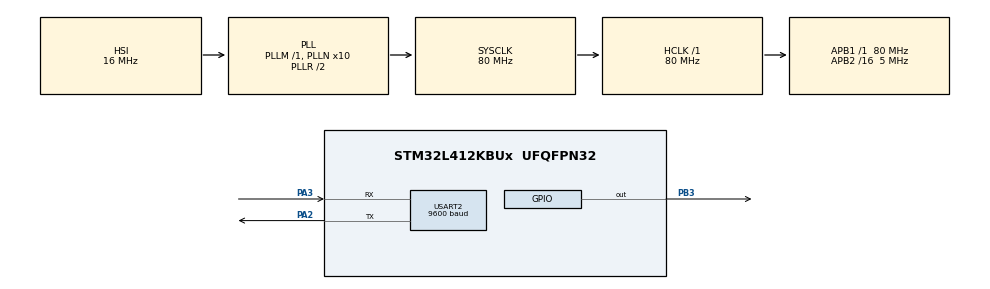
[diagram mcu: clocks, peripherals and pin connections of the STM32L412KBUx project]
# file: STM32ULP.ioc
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Mcu.Family=STM32L4
Mcu.Name=STM32L412KBUx
Mcu.Package=UFQFPN32
NVIC.PriorityGroup=NVIC_PRIORITYGROUP_4
NVIC.RTC_WKUP_IRQn=true\:0\:0\:false\:false\:true\:true\:true\:true
PA2.Mode=Asynchronous
PA2.Signal=USART2_TX
PA3.Mode=Asynchronous
PA3.Signal=USART2_RX
PB3\ (JTDO/TRACESWO).Signal=GPIO_Output
ProjectManager.HeapSize=0x200
ProjectManager.StackSize=0x400
ProjectManager.TargetToolchain=STM32CubeIDE
RCC.ADCFreq_Value=80000000
RCC.AHBFreq_Value=80000000
RCC.APB1Freq_Value=80000000
RCC.APB1TimFreq_Value=80000000
RCC.APB2CLKDivider=RCC_HCLK_DIV16
RCC.APB2Freq_Value=5000000
RCC.APB2TimFreq_Value=10000000
RCC.CortexFreq_Value=10000000
RCC.Cortex_Div=SYSTICK_CLKSOURCE_HCLK_DIV8
RCC.HCLKFreq_Value=80000000
RCC.HSE_VALUE=8000000
RCC.HSI48_VALUE=48000000
RCC.HSI_VALUE=16000000
RCC.LSE_VALUE=32768
RCC.MSIClockRange=RCC_MSIRANGE_11
RCC.MSI_VALUE=48000000
RCC.PLLN=10
RCC.PLLSourceVirtual=RCC_PLLSOURCE_HSI
RCC.SYSCLKFreq_VALUE=80000000
RCC.SYSCLKSource=RCC_SYSCLKSOURCE_PLLCLK
RCC.USART1CLockSelection=RCC_USART1CLKSOURCE_HSI
RCC.USART2CLockSelection=RCC_USART2CLKSOURCE_SYSCLK
RCC.USBFreq_Value=48000000
RCC.VCOOutputFreq_Value=160000000
RTC.WakeUpClock=RTC_WAKEUPCLOCK_RTCCLK_DIV16
RTC.WakeUpCounter=20490
USART2.BaudRate=9600
USART2.VirtualMode-Asynchronous=VM_ASYNC
VP_RTC_VS_RTC_Activate.Mode=RTC_Enabled
VP_RTC_VS_RTC_WakeUp_intern.Mode=WakeUp
VP_SYS_VS_DBSignals.Mode=DisableDeadBatterySignals
board=custom

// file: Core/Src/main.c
/* USER CODE BEGIN Header */
/**
  ******************************************************************************
  * @file           : main.c
  * @brief          : Main program body
  ******************************************************************************
  * @attention
  *
  * Copyright (c) 2024 STMicroelectronics.
  * All rights reserved.
  *
  * This software is licensed under terms that can be found in the LICENSE file
  * in the root directory of this software component.
  * If no LICENSE file comes with this software, it is provided AS-IS.
  *
  ******************************************************************************
  */
#include <stdio.h>
/* USER CODE END Header */
#include "main.h"

RTC_HandleTypeDef hrtc;

UART_HandleTypeDef huart2;

void SystemClock_Config(void);
static void MX_GPIO_Init(void);
static void MX_RTC_Init(void);
static void MX_USART2_UART_Init(void);

/* USER CODE BEGIN 0 */
void HAL_UARTEx_EnableLowPower(UART_HandleTypeDef *huart) {
    // This function ensures that UART remains active in low-power modes
    if (huart->Instance == USART2) {
        __HAL_RCC_USART2_CLK_ENABLE();  // Ensure USART2 clock is enabled
        huart->Init.Mode = UART_MODE_TX_RX;  // Ensure both TX and RX are enabled
        huart->Init.OverSampling = UART_OVERSAMPLING_16;  // OverSampling

        // Apply the configuration changes
        if (HAL_UART_Init(huart) != HAL_OK) {
            // Initialization error, handle it here
            Error_Handler();
        }
    }
}

/* USER CODE END 0 */

int main(void)
{

  /* USER CODE BEGIN 1 */
	char MSG[46] = {'\0'};

  /* USER CODE END 1 */

  /* MCU Configuration--------------------------------------------------------*/

  /* Reset of all peripherals, Initializes the Flash interface and the Systick. */
  HAL_Init();

  /* Configure the system clock */
  SystemClock_Config();

  /* Initialize all configured peripherals */
  MX_GPIO_Init();
  MX_RTC_Init();
  MX_USART2_UART_Init();

  /* Infinite loop */
  /* USER CODE BEGIN WHILE */
  while (1)
  {
	  // Reconfigure system clocks after waking up
	  SystemClock_Config();

	  // Reinitialize UART
	  HAL_UART_Init(&huart2);

	  //Print value stored in backup register to serial port
	  sprintf(MSG,"Value in backup register 7 is: %lu \r\n", HAL_RTCEx_BKUPRead(&hrtc, RTC_BKP_DR7));
	  HAL_UART_Transmit(&huart2, MSG, sizeof(MSG),HAL_MAX_DELAY);

	  //Enter STOP mode
	  HAL_PWR_EnterSTOPMode(PWR_LOWPOWERREGULATOR_ON, PWR_STOPENTRY_WFI);
    /* USER CODE END WHILE */

    /* USER CODE BEGIN 3 */
	 // Once the system wakes up, reinitialize clocks and UART

  }
  /* USER CODE END 3 */
}

void SystemClock_Config(void)
{
  RCC_OscInitTypeDef RCC_OscInitStruct = {0};
  RCC_ClkInitTypeDef RCC_ClkInitStruct = {0};

  /** Configure the main internal regulator output voltage
  */
  if (HAL_PWREx_ControlVoltageScaling(PWR_REGULATOR_VOLTAGE_SCALE1) != HAL_OK)
  {
    Error_Handler();
  }

  /** Initializes the RCC Oscillators according to the specified parameters
  * in the RCC_OscInitTypeDef structure.
  */
  RCC_OscInitStruct.OscillatorType = RCC_OSCILLATORTYPE_HSI|RCC_OSCILLATORTYPE_LSI;
  RCC_OscInitStruct.HSIState = RCC_HSI_ON;
  RCC_OscInitStruct.HSICalibrationValue = RCC_HSICALIBRATION_DEFAULT;
  RCC_OscInitStruct.LSIState = RCC_LSI_ON;
  RCC_OscInitStruct.PLL.PLLState = RCC_PLL_ON;
  RCC_OscInitStruct.PLL.PLLSource = RCC_PLLSOURCE_HSI;
  RCC_OscInitStruct.PLL.PLLM = 1;
  RCC_OscInitStruct.PLL.PLLN = 10;
  RCC_OscInitStruct.PLL.PLLQ = RCC_PLLQ_DIV2;
  RCC_OscInitStruct.PLL.PLLR = RCC_PLLR_DIV2;
  if (HAL_RCC_OscConfig(&RCC_OscInitStruct) != HAL_OK)
  {
    Error_Handler();
  }

  /** Initializes the CPU, AHB and APB buses clocks
  */
  RCC_ClkInitStruct.ClockType = RCC_CLOCKTYPE_HCLK|RCC_CLOCKTYPE_SYSCLK
                              |RCC_CLOCKTYPE_PCLK1|RCC_CLOCKTYPE_PCLK2;
  RCC_ClkInitStruct.SYSCLKSource = RCC_SYSCLKSOURCE_PLLCLK;
  RCC_ClkInitStruct.AHBCLKDivider = RCC_SYSCLK_DIV1;
  RCC_ClkInitStruct.APB1CLKDivider = RCC_HCLK_DIV1;
  RCC_ClkInitStruct.APB2CLKDivider = RCC_HCLK_DIV16;

  if (HAL_RCC_ClockConfig(&RCC_ClkInitStruct, FLASH_LATENCY_4) != HAL_OK)
  {
    Error_Handler();
  }
}

static void MX_RTC_Init(void)
{

  /** Initialize RTC Only
  */
  hrtc.Instance = RTC;
  hrtc.Init.HourFormat = RTC_HOURFORMAT_24;
  hrtc.Init.AsynchPrediv = 127;
  hrtc.Init.SynchPrediv = 255;
  hrtc.Init.OutPut = RTC_OUTPUT_DISABLE;
  hrtc.Init.OutPutRemap = RTC_OUTPUT_REMAP_NONE;
  hrtc.Init.OutPutPolarity = RTC_OUTPUT_POLARITY_HIGH;
  hrtc.Init.OutPutType = RTC_OUTPUT_TYPE_OPENDRAIN;
  hrtc.Init.OutPutPullUp = RTC_OUTPUT_PULLUP_NONE;
  if (HAL_RTC_Init(&hrtc) != HAL_OK)
  {
    Error_Handler();
  }

  /** Enable the WakeUp
  */
  if (HAL_RTCEx_SetWakeUpTimer_IT(&hrtc, 20490, RTC_WAKEUPCLOCK_RTCCLK_DIV16, 0) != HAL_OK)
  {
    Error_Handler();
  }

}

static void MX_USART2_UART_Init(void)
{

  huart2.Instance = USART2;
  huart2.Init.BaudRate = 9600;
  huart2.Init.WordLength = UART_WORDLENGTH_8B;
  huart2.Init.StopBits = UART_STOPBITS_1;
  huart2.Init.Parity = UART_PARITY_NONE;
  huart2.Init.Mode = UART_MODE_TX_RX;
  huart2.Init.HwFlowCtl = UART_HWCONTROL_NONE;
  huart2.Init.OverSampling = UART_OVERSAMPLING_16;
  huart2.Init.OneBitSampling = UART_ONE_BIT_SAMPLE_DISABLE;
  huart2.AdvancedInit.AdvFeatureInit = UART_ADVFEATURE_NO_INIT;
  if (HAL_UART_Init(&huart2) != HAL_OK)
  {
    Error_Handler();
  }
  /* USER CODE BEGIN USART2_Init 2 */
  // Enable USART2 in low-power mode
  HAL_UARTEx_EnableLowPower(&huart2);

  /* USER CODE END USART2_Init 2 */

}

static void MX_GPIO_Init(void)
{
  GPIO_InitTypeDef GPIO_InitStruct = {0};

  /* GPIO Ports Clock Enable */
  __HAL_RCC_GPIOA_CLK_ENABLE();
  __HAL_RCC_GPIOB_CLK_ENABLE();

  /*Configure GPIO pin Output Level */
  HAL_GPIO_WritePin(GPIOB, GPIO_PIN_3, GPIO_PIN_RESET);

  /*Configure GPIO pin : PB3 */
  GPIO_InitStruct.Pin = GPIO_PIN_3;
  GPIO_InitStruct.Mode = GPIO_MODE_OUTPUT_PP;
  GPIO_InitStruct.Pull = GPIO_NOPULL;
  GPIO_InitStruct.Speed = GPIO_SPEED_FREQ_LOW;
  HAL_GPIO_Init(GPIOB, &GPIO_InitStruct);

}

void Error_Handler(void)
{
  __disable_irq();
  while (1)
  {
  }
}
